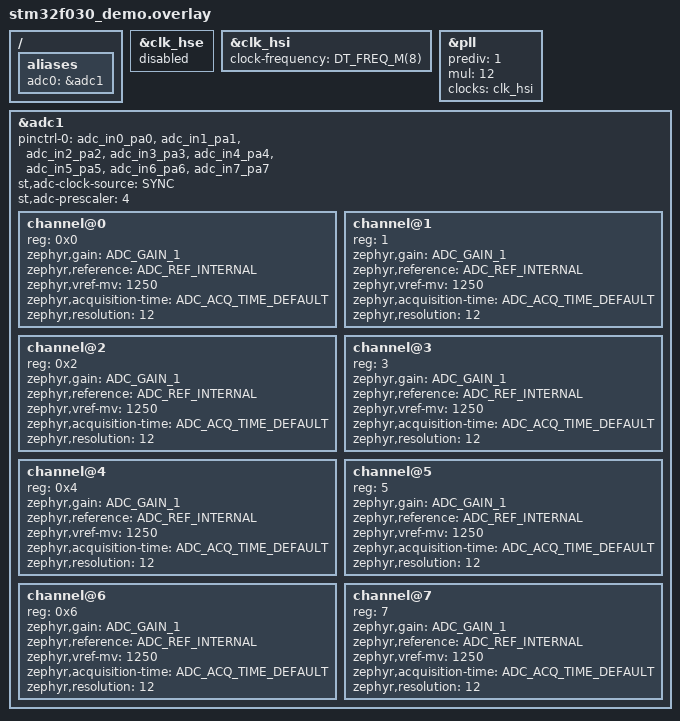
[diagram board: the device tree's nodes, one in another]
/*
 * Copyright 2025 NXP
 *
 * SPDX-License-Identifier: Apache-2.0
 */

/ {
	aliases {
		adc0 = &adc1;
	};
};

&clk_hse {
	status = "disabled";
};

&clk_hsi {
	clock-frequency = <DT_FREQ_M(8)>;
	status = "okay";
};

&pll {
	prediv = <1>;
	mul = <12>;
	clocks = <&clk_hsi>;
	status = "okay";
};

&adc1 {
	#address-cells = <1>;
	#size-cells = <0>;
	pinctrl-0 = <&adc_in0_pa0 &adc_in1_pa1 &adc_in2_pa2 &adc_in3_pa3
			&adc_in4_pa4 &adc_in5_pa5 &adc_in6_pa6 &adc_in7_pa7>;
	pinctrl-names = "default";
	st,adc-clock-source = "SYNC";
	st,adc-prescaler = <4>;
	status = "okay";

	channel@0 {
		reg = <0x0>;
		zephyr,gain = "ADC_GAIN_1";
		zephyr,reference = "ADC_REF_INTERNAL";
		zephyr,vref-mv = <1250>;
		zephyr,acquisition-time = <ADC_ACQ_TIME_DEFAULT>;
		zephyr,resolution = <12>;
	};

	channel@1 {
		reg = <1>;
		zephyr,gain = "ADC_GAIN_1";
		zephyr,reference = "ADC_REF_INTERNAL";
		zephyr,vref-mv = <1250>;
		zephyr,acquisition-time = <ADC_ACQ_TIME_DEFAULT>;
		zephyr,resolution = <12>;
	};

	channel@2 {
		reg = <0x2>;
		zephyr,gain = "ADC_GAIN_1";
		zephyr,reference = "ADC_REF_INTERNAL";
		zephyr,vref-mv = <1250>;
		zephyr,acquisition-time = <ADC_ACQ_TIME_DEFAULT>;
		zephyr,resolution = <12>;
	};

	channel@3 {
		reg = <3>;
		zephyr,gain = "ADC_GAIN_1";
		zephyr,reference = "ADC_REF_INTERNAL";
		zephyr,vref-mv = <1250>;
		zephyr,acquisition-time = <ADC_ACQ_TIME_DEFAULT>;
		zephyr,resolution = <12>;
	};

	channel@4 {
		reg = <0x4>;
		zephyr,gain = "ADC_GAIN_1";
		zephyr,reference = "ADC_REF_INTERNAL";
		zephyr,vref-mv = <1250>;
		zephyr,acquisition-time = <ADC_ACQ_TIME_DEFAULT>;
		zephyr,resolution = <12>;
	};

	channel@5 {
		reg = <5>;
		zephyr,gain = "ADC_GAIN_1";
		zephyr,reference = "ADC_REF_INTERNAL";
		zephyr,vref-mv = <1250>;
		zephyr,acquisition-time = <ADC_ACQ_TIME_DEFAULT>;
		zephyr,resolution = <12>;
	};

	channel@6 {
		reg = <0x6>;
		zephyr,gain = "ADC_GAIN_1";
		zephyr,reference = "ADC_REF_INTERNAL";
		zephyr,vref-mv = <1250>;
		zephyr,acquisition-time = <ADC_ACQ_TIME_DEFAULT>;
		zephyr,resolution = <12>;
	};

	channel@7 {
		reg = <7>;
		zephyr,gain = "ADC_GAIN_1";
		zephyr,reference = "ADC_REF_INTERNAL";
		zephyr,vref-mv = <1250>;
		zephyr,acquisition-time = <ADC_ACQ_TIME_DEFAULT>;
		zephyr,resolution = <12>;
	};
};
